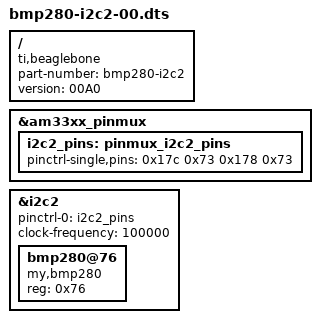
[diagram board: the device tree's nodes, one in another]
/dts-v1/;
/plugin/;
/ {
	compatible = "ti,beaglebone", "ti,beaglebone-black";

	part-number = "bmp280-i2c2";
	version = "00A0";

	fragment@0 {
		target = <&am33xx_pinmux>;
		__overlay__ {
			i2c2_pins: pinmux_i2c2_pins {
				pinctrl-single,pins = <
					0x17c 0x73	/* P9_19: uart1_rtsn.i2c2_scl, SLEWCTRL_SLOW | INPUT_PULLUP | MODE3 */
					0x178 0x73	/* P9_20: uart1_ctsn.i2c2_sda, SLEWCTRL_SLOW | INPUT_PULLUP | MODE3 */
				>;
			};
		};
	};

	fragment@1 {
		target = <&i2c2>;
		__overlay__ {
			status = "okay";
			pinctrl-names = "default";
			pinctrl-0 = <&i2c2_pins>;
			
			clock-frequency = <100000>;
			#address-cells = <1>;
			#size-cells = <0>;

			bmp280@76 {
				compatible = "my,bmp280";
				reg = <0x76>;
				status = "okay";
			};
		};
	};
};
